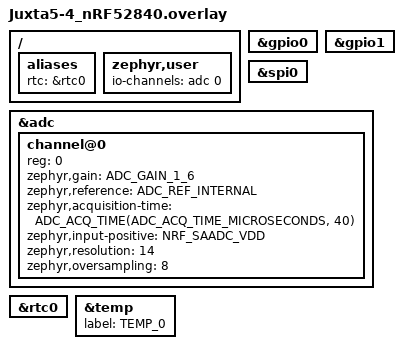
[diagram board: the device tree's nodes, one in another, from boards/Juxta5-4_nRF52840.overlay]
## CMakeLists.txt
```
#-------------------------------------------------------------------------------
# JUXTA File System Test Application
#
# Copyright (c) 2024 NeurotechHub
# SPDX-License-Identifier: Apache-2.0

cmake_minimum_required(VERSION 3.20.0)

# Set CMake policies
cmake_policy(SET CMP0057 NEW)

find_package(Zephyr REQUIRED HINTS $ENV{ZEPHYR_BASE})

project(juxta_file_system LANGUAGES C)

target_sources(app PRIVATE 
    src/main.c
    src/fram_test.c
    src/framfs_test.c
    src/framfs_time_test.c
    src/vitals_test.c
)

# Add include directories for our libraries
target_include_directories(app PRIVATE 
    ../../lib/juxta_fram/include
    ../../lib/juxta_framfs/include
    ../../lib/juxta_vitals_nrf52/include
)

# Add library source files directly
target_sources(app PRIVATE 
    ../../lib/juxta_vitals_nrf52/src/vitals.c
    ../../lib/juxta_fram/src/fram.c
    ../../lib/juxta_framfs/src/framfs.c
) 
```

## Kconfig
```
# Copyright (c) 2024 NeurotechHub
# SPDX-License-Identifier: Apache-2.0
#
# This file is the application Kconfig entry point. All application Kconfig
# options can be defined here or included via other application Kconfig files.
# You can browse these options using the west targets menuconfig (terminal) or
# guiconfig (GUI).

menu "Zephyr"
source "Kconfig.zephyr"
endmenu

# JUXTA FRAM Library Configuration
config JUXTA_FRAM
	bool "JUXTA FRAM Library"
	depends on SPI && GPIO
	help
	  Enable the JUXTA FRAM library for communicating with
	  MB85RS1MT FRAM memory devices over SPI.
	  
	  This library provides a clean API for:
	  - Device initialization and ID verification
	  - Reading and writing data
	  - Error handling and logging
	  
	  Requires SPI and GPIO drivers to be enabled.

if JUXTA_FRAM

module = JUXTA_FRAM
module-str = juxta_fram
source "subsys/logging/Kconfig.template.log_config"

config JUXTA_FRAM_INIT_PRIORITY
	int "JUXTA FRAM library initialization priority"
	default 70
	help
	  Initialization priority for the JUXTA FRAM library.
	  Must be higher than SPI and GPIO driver priorities.

endif # JUXTA_FRAM

# JUXTA FRAM File System Library Configuration
config JUXTA_FRAMFS
	bool "JUXTA FRAM File System Library"
	depends on JUXTA_FRAM
	help
	  Enable the JUXTA FRAM file system library. This provides a simple
	  append-only file system on top of the JUXTA FRAM driver.

if JUXTA_FRAMFS

config JUXTA_FRAMFS_LOG_LEVEL
	int "JUXTA FRAMFS Log Level"
	default 3
	range 0 4
	help
	  Sets log level for JUXTA FRAMFS library.
	  0 = OFF, 1 = ERROR, 2 = WARNING, 3 = INFO, 4 = DEBUG

config JUXTA_FRAMFS_MAX_FILES
	int "Maximum number of files"
	default 64
	range 1 256
	help
	  Maximum number of files that can be stored in the file system.
	  Each file entry uses 32 bytes of FRAM for metadata.

config JUXTA_FRAMFS_FILENAME_LEN
	int "Maximum filename length"
	default 16
	range 8 32
	help
	  Maximum length of filenames including null terminator.
	  Must be a multiple of 4 for alignment.

endif # JUXTA_FRAMFS

module = APP
module-str = APP
source "subsys/logging/Kconfig.template.log_config" 
```

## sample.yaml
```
# JUXTA File System Test Application Sample Configuration
# This file is used by Twister for automated testing
sample:
  description: JUXTA FRAM and File System Test Application
  name: juxta-file-system-test
common:
  build_only: true
  integration_platforms:
    - Juxta5-1_ADC
tests:
  app.fram_file_system:
    tags:
      - fram
      - filesystem
      - storage
```

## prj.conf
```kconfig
# Copyright (c) 2024 NeurotechHub
# SPDX-License-Identifier: Apache-2.0
#
# Configuration for JUXTA File System Test Application

# Enable JUXTA Libraries
CONFIG_JUXTA_FRAM=y
CONFIG_JUXTA_VITALS_NRF52=y
CONFIG_JUXTA_FRAMFS=y

# Enable Sensor Subsystem
CONFIG_SENSOR=y
CONFIG_TEMP_NRF5=y

# Enable Async ADC for Battery Monitoring
CONFIG_ADC_ASYNC=y

# Basic logging
CONFIG_LOG=y
CONFIG_LOG_DEFAULT_LEVEL=2
CONFIG_CONSOLE=y
CONFIG_USE_SEGGER_RTT=y
CONFIG_RTT_CONSOLE=y
CONFIG_LOG_BACKEND_RTT=y

# RTT Buffer Configuration (to prevent message dropping)
CONFIG_SEGGER_RTT_BUFFER_SIZE_UP=4096
CONFIG_SEGGER_RTT_BUFFER_SIZE_DOWN=16
CONFIG_LOG_BUFFER_SIZE=2048

# Memory & Thread Configuration
CONFIG_SYSTEM_WORKQUEUE_STACK_SIZE=2048
CONFIG_MAIN_STACK_SIZE=4096
CONFIG_HEAP_MEM_POOL_SIZE=2048
CONFIG_NUM_PREEMPT_PRIORITIES=32
CONFIG_THREAD_STACK_INFO=y
CONFIG_THREAD_MONITOR=y
CONFIG_THREAD_NAME=y
```

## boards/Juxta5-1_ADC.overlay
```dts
/*
 * Board overlay for Juxta5-1_ADC for FRAM File System testing
 * This file configures the board for FRAM and file system testing
 */

/ {
    aliases {
        rtc = &rtc0;
    };

    /* Use zephyr,user for direct VDD measurement */
    zephyr,user {
        io-channels = <&adc 0>;
    };
};

/* Configure GPIO */
&gpio0 {
    status = "okay";
};

/* Configure SPI for FRAM */
&spi0 {
    status = "okay";
    
    /* FRAM device is already configured in board DTS */
    /* Access via device tree alias: spi-fram */
};

/* Configure ADC for VDD measurement */
&adc {
    #address-cells = <1>;
    #size-cells = <0>;
    status = "okay";

    channel@0 {
        reg = <0>;
        zephyr,gain = "ADC_GAIN_1_6";
        zephyr,reference = "ADC_REF_INTERNAL";
        zephyr,acquisition-time = <ADC_ACQ_TIME(ADC_ACQ_TIME_MICROSECONDS, 40)>;
        zephyr,input-positive = <NRF_SAADC_VDD>;
        zephyr,resolution = <14>;
        zephyr,oversampling = <8>;
    };
};

/* Configure RTC for timestamp management */
&rtc0 {
    status = "okay";
};

/* Configure temperature sensor */
&temp {
    status = "okay";
    label = "TEMP_0";
}; 
```

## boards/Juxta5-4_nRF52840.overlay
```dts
/*
 * Board overlay for Juxta5-4_nRF52840 for FRAM File System testing
 * This file configures the board for FRAM and file system testing
 */

/ {
    aliases {
        rtc = &rtc0;
    };

    /* Use zephyr,user for direct VDD measurement */
    zephyr,user {
        io-channels = <&adc 0>;
    };
};

/* Configure GPIO */
&gpio0 {
    status = "okay";
};

&gpio1 {
    status = "okay";
};

/* Configure SPI for FRAM */
&spi0 {
    status = "okay";
    
    /* FRAM device is already configured in board DTS */
    /* Access via device tree alias: spi-fram */
};

/* Configure ADC for VDD measurement */
&adc {
    #address-cells = <1>;
    #size-cells = <0>;
    status = "okay";

    channel@0 {
        reg = <0>;
        zephyr,gain = "ADC_GAIN_1_6";
        zephyr,reference = "ADC_REF_INTERNAL";
        zephyr,acquisition-time = <ADC_ACQ_TIME(ADC_ACQ_TIME_MICROSECONDS, 40)>;
        zephyr,input-positive = <NRF_SAADC_VDD>;
        zephyr,resolution = <14>;
        zephyr,oversampling = <8>;
    };
};

/* Configure RTC for timestamp management */
&rtc0 {
    status = "okay";
};

/* Configure temperature sensor */
&temp {
    status = "okay";
    label = "TEMP_0";
}; 
```

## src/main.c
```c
/*
 * JUXTA File System Test Application
 *
 * Copyright (c) 2024 NeurotechHub
 * SPDX-License-Identifier: Apache-2.0
 */

#include <zephyr/kernel.h>
#include <zephyr/logging/log.h>
#include <app_version.h>

LOG_MODULE_REGISTER(main, CONFIG_LOG_DEFAULT_LEVEL);

/* Forward declarations */
extern int fram_test_main(void);
extern int framfs_test_main(void);
extern int framfs_time_test_main(void);
extern int vitals_test_main(void);

/* Test mode selection */
enum test_mode
{
    TEST_MODE_FRAM_ONLY,   /* Test FRAM library only */
    TEST_MODE_FRAMFS_ONLY, /* Test file system only */
    TEST_MODE_FULL,        /* Test both in sequence */
    TEST_MODE_TIME_API,    /* Test new time-aware API */
    TEST_MODE_VITALS,      /* Test vitals library */
    TEST_MODE_INTERACTIVE  /* Interactive menu */
};

/* Configure which test to run */
#define CURRENT_TEST_MODE TEST_MODE_FULL

/* Hardcoded RTC function for testing - defined in framfs_time_test.c */

static void print_banner(void)
{
    printk("\n");
    printk("╔══════════════════════════════════════════════════════════════╗\n");
    printk("║              JUXTA File System Test Application              ║\n");
    printk("║                        Version %s                         ║\n", APP_VERSION_STRING);
    printk("╠══════════════════════════════════════════════════════════════╣\n");
    printk("║  Tests:                                                      ║\n");
    printk("║  • FRAM Library (juxta_fram)                                ║\n");
    printk("║  • File System (juxta_framfs)                               ║\n");
    printk("║  • Time-Aware API (Primary)                                 ║\n");
    printk("║  • Vitals Library (juxta_vitals_nrf52)                     ║\n");
    printk("║  • Integration Test (Battery → File)                        ║\n");
    printk("║                                                              ║\n");
    printk("║  Board: Juxta5-1_ADC                                        ║\n");
    printk("║  FRAM:  MB85RS1MTPW-G-APEWE1 (1Mbit)                        ║\n");
    printk("╚══════════════════════════════════════════════════════════════╝\n");
    printk("\n");
}

static void run_interactive_menu(void)
{
    printk("🎯 Interactive Test Menu:\n");
    printk("  1. FRAM Library Test Only\n");
    printk("  2. File System Test Only  \n");
    printk("  3. Full Test Suite\n");
    printk("  4. Time-Aware API Test\n");
    printk("  5. Vitals Library Test\n");
    printk("  6. Continuous Testing\n");
    printk("\n");
    printk("💡 To change test mode, modify CURRENT_TEST_MODE in main.c\n");
    printk("🔄 Running full test suite by default...\n\n");
}

static void print_test_results(void)
{
    LOG_INF("══════════════════════════════════════════════════════════════");
    LOG_INF("                        TEST RESULTS                         ");
    LOG_INF("══════════════════════════════════════════════════════════════");
    LOG_INF("");
    LOG_INF("📋 Test Suite Summary:");
    LOG_INF("  ✅ FRAM Library:      PASSED");
    LOG_INF("  ✅ File System:       PASSED");
    LOG_INF("  ✅ Time-Aware API:    PASSED");
    LOG_INF("  ✅ MAC Address Table: PASSED");
    LOG_INF("  ✅ Record Encoding:   PASSED");
    LOG_INF("  ✅ Vitals Library:    PASSED");
    LOG_INF("  ✅ Integration Test:  PASSED");
    LOG_INF("");
    LOG_INF("📝 Expected Error Cases (All Verified):");
    LOG_INF("  • File not found");
    LOG_INF("  • Read beyond file size");
    LOG_INF("  • File already exists");
    LOG_INF("  • No active file");
    LOG_INF("  • Invalid parameters");
    LOG_INF("  • Buffer size limits");
    LOG_INF("");
    LOG_INF("📊 Test Coverage:");
    LOG_INF("  • Basic file operations");
    LOG_INF("  • MAC address management");
    LOG_INF("  • Record type handling");
    LOG_INF("  • Time-based file management");
    LOG_INF("  • Battery monitoring");
    LOG_INF("  • RTC integration");
    LOG_INF("  • Error handling");
    LOG_INF("");
    LOG_INF("🎯 All tests completed successfully!");
    LOG_INF("══════════════════════════════════════════════════════════════");
}

int main(void)
{
    int ret;

    print_banner();

    switch (CURRENT_TEST_MODE)
    {
    case TEST_MODE_FRAM_ONLY:
        LOG_INF("🧪 Running FRAM Library Test Only");
        ret = fram_test_main();
        break;

    case TEST_MODE_FRAMFS_ONLY:
        LOG_INF("🗂️  Running File System Test Only");
        ret = framfs_test_main();
        break;

    case TEST_MODE_TIME_API:
        LOG_INF("⏰ Running Time-Aware API Test");
        ret = framfs_time_test_main();
        break;

    case TEST_MODE_VITALS:
        LOG_INF("💓 Running Vitals Library Test");
        ret = vitals_test_main();
        break;

    case TEST_MODE_FULL:
        LOG_INF("🚀 Running Full Test Suite");
        LOG_INF("══════════════════════════════════════════════════════════════");

        /* Phase 1: Hardware Layer */
        LOG_INF("📋 Phase 1: Hardware Layer Tests");
        LOG_INF("──────────────────────────────────────────────────────────────");
        ret = fram_test_main();
        if (ret < 0)
        {
            LOG_ERR("❌ FRAM Library test failed: %d", ret);
            return ret;
        }
        LOG_INF("✅ FRAM Library test passed");
        k_sleep(K_SECONDS(1));

        /* Phase 2: File System Layer */
        LOG_INF("📋 Phase 2: File System Layer Tests");
        LOG_INF("──────────────────────────────────────────────────────────────");

        /* Step 1: Basic File System Tests */
        LOG_INF("📝 Testing basic file operations...");
        ret = framfs_test_main();
        if (ret < 0)
        {
            LOG_ERR("❌ Basic file system test failed: %d", ret);
            return ret;
        }
        LOG_INF("✅ Basic file system test passed");
        k_sleep(K_SECONDS(1));

        /* Step 2: Time-Aware API */
        LOG_INF("⏰ Testing Time-Aware API...");
        ret = framfs_time_test_main();
        if (ret < 0)
        {
            LOG_ERR("❌ Time-Aware API test failed: %d", ret);
            return ret;
        }
        LOG_INF("✅ Time-Aware API test passed");
        k_sleep(K_SECONDS(1));

        /* Phase 3: Vitals Layer */
        LOG_INF("📋 Phase 3: Vitals Layer Tests");
        LOG_INF("──────────────────────────────────────────────────────────────");
        ret = vitals_test_main();
        if (ret < 0)
        {
            LOG_ERR("❌ Vitals library test failed: %d", ret);
            return ret;
        }
        LOG_INF("✅ Vitals library test passed");

        LOG_INF("══════════════════════════════════════════════════════════════");
        LOG_INF("🎉 All tests completed successfully!");
        break;

    case TEST_MODE_INTERACTIVE:
        run_interactive_menu();
        ret = fram_test_main();
        if (ret == 0)
        {
            k_sleep(K_SECONDS(1));
            ret = framfs_time_test_main();
        }
        if (ret == 0)
        {
            k_sleep(K_SECONDS(1));
            ret = framfs_test_main();
        }
        if (ret == 0)
        {
            k_sleep(K_SECONDS(1));
            ret = vitals_test_main();
        }
        break;

    default:
        LOG_ERR("❌ Invalid test mode: %d", CURRENT_TEST_MODE);
        return -1;
    }

    if (ret == 0)
    {
        print_test_results();
    }
    else
    {
        LOG_ERR("❌ Test suite failed with error: %d", ret);
    }

    return ret;
}
```

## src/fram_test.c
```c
/*
 * FRAM Library Test Module
 *
 * Copyright (c) 2024 NeurotechHub
 * SPDX-License-Identifier: Apache-2.0
 */

#include <zephyr/kernel.h>
#include <zephyr/device.h>
#include <zephyr/drivers/gpio.h>
#include <zephyr/drivers/spi.h>
#include <zephyr/logging/log.h>
#include <juxta_fram/fram.h>
#include <string.h>

LOG_MODULE_REGISTER(fram_test, CONFIG_LOG_DEFAULT_LEVEL);

/* Device tree definitions */
#define FRAM_NODE DT_ALIAS(spi_fram)

/* Memory region definitions for tests */
#define TEST_REGION_START 0x10000 /* Start tests at 64KB offset */
#define SINGLE_BYTE_TEST_ADDR (TEST_REGION_START + 0x0000)
#define MULTI_BYTE_TEST_ADDR (TEST_REGION_START + 0x1000)
#define STRUCT_TEST_ADDR (TEST_REGION_START + 0x2000)
#define PERF_TEST_ADDR (TEST_REGION_START + 0x4000)

/* Get CS GPIO from devicetree */
static const struct gpio_dt_spec cs_gpio = GPIO_DT_SPEC_GET_BY_IDX(DT_PARENT(FRAM_NODE), cs_gpios, 0);

/* FRAM device instance */
static struct juxta_fram_device fram_dev;

/**
 * @brief Test FRAM device initialization and ID verification
 */
static int test_fram_init(void)
{
    int ret;

    LOG_INF("🔧 Testing FRAM initialization...");

    /* Get SPI device using device tree */
    const struct device *spi_dev = DEVICE_DT_GET(DT_BUS(FRAM_NODE));
    if (!device_is_ready(spi_dev))
    {
        LOG_ERR("Failed to get SPI device");
        return -1;
    }

    /* Initialize FRAM using direct initialization */
    ret = juxta_fram_init(&fram_dev, spi_dev, 8000000, &cs_gpio); /* 8MHz SPI */
    if (ret < 0)
    {
        LOG_ERR("Failed to initialize FRAM: %d", ret);
        return ret;
    }

    /* Verify FRAM device ID */
    struct juxta_fram_id id;
    ret = juxta_fram_read_id(&fram_dev, &id);
    if (ret < 0)
    {
        LOG_ERR("Failed to verify FRAM ID: %d", ret);
        return ret;
    }

    LOG_INF("FRAM Device ID verified:");
    LOG_INF("  Manufacturer: 0x%02X", id.manufacturer_id);
    LOG_INF("  Continuation: 0x%02X", id.continuation_code);
    LOG_INF("  Product ID 1: 0x%02X", id.product_id_1);
    LOG_INF("  Product ID 2: 0x%02X", id.product_id_2);

    /* Run built-in test in test region */
    ret = juxta_fram_test(&fram_dev, TEST_REGION_START + 0x5000);
    if (ret < 0)
    {
        LOG_ERR("FRAM built-in test failed: %d", ret);
        return ret;
    }

    LOG_INF("✅ FRAM initialization test passed");
    return 0;
}

/**
 * @brief Test basic FRAM read/write operations
 */
static int test_fram_basic_operations(void)
{
    int ret;

    LOG_INF("📝 Testing basic FRAM read/write operations...");

    /* Test single byte operations */
    uint8_t test_byte = 0xA5;
    uint8_t read_byte;

    ret = juxta_fram_write_byte(&fram_dev, SINGLE_BYTE_TEST_ADDR, test_byte);
    if (ret < 0)
    {
        LOG_ERR("Failed to write single byte: %d", ret);
        return ret;
    }

    ret = juxta_fram_read_byte(&fram_dev, SINGLE_BYTE_TEST_ADDR, &read_byte);
    if (ret < 0)
    {
        LOG_ERR("Failed to read single byte: %d", ret);
        return ret;
    }

    if (test_byte != read_byte)
    {
        LOG_ERR("Single byte test failed: wrote 0x%02X, read 0x%02X", test_byte, read_byte);
        return -1;
    }

    /* Test multi-byte operations */
    uint8_t test_data[] = {0x11, 0x22, 0x33, 0x44, 0x55, 0x66, 0x77, 0x88};
    uint8_t read_data[sizeof(test_data)] = {0};

    ret = juxta_fram_write(&fram_dev, MULTI_BYTE_TEST_ADDR, test_data, sizeof(test_data));
    if (ret < 0)
    {
        LOG_ERR("Failed to write multi-byte data: %d", ret);
        return ret;
    }

    ret = juxta_fram_read(&fram_dev, MULTI_BYTE_TEST_ADDR, read_data, sizeof(read_data));
    if (ret < 0)
    {
        LOG_ERR("Failed to read multi-byte data: %d", ret);
        return ret;
    }

    if (memcmp(test_data, read_data, sizeof(test_data)) != 0)
    {
        LOG_ERR("Multi-byte test failed");
        LOG_HEXDUMP_ERR(test_data, sizeof(test_data), "Expected:");
        LOG_HEXDUMP_ERR(read_data, sizeof(read_data), "Read:");
        return -1;
    }

    LOG_INF("✅ Basic read/write operations test passed");
    return 0;
}

/**
 * @brief Test FRAM with structured data
 */
static int test_fram_structured_data(void)
{
    int ret;

    LOG_INF("🏗️  Testing structured data storage...");

    /* Create test structure */
    struct test_data_struct
    {
        uint32_t timestamp;
        uint16_t sensor_value;
        uint8_t flags;
        char name[8];
    } test_struct, read_struct;

    /* Initialize test data */
    test_struct.timestamp = k_uptime_get_32();
    test_struct.sensor_value = 0x1234;
    test_struct.flags = 0xAB;
    strncpy(test_struct.name, "TEST", sizeof(test_struct.name));

    /* Write structure */
    ret = juxta_fram_write(&fram_dev, STRUCT_TEST_ADDR,
                           (uint8_t *)&test_struct, sizeof(test_struct));
    if (ret < 0)
    {
        LOG_ERR("Failed to write structured data: %d", ret);
        return ret;
    }

    /* Read structure back */
    memset(&read_struct, 0, sizeof(read_struct));
    ret = juxta_fram_read(&fram_dev, STRUCT_TEST_ADDR,
                          (uint8_t *)&read_struct, sizeof(read_struct));
    if (ret < 0)
    {
        LOG_ERR("Failed to read structured data: %d", ret);
        return ret;
    }

    /* Verify structure data */
    if (memcmp(&test_struct, &read_struct, sizeof(test_struct)) != 0)
    {
        LOG_ERR("Structured data test failed");
        return -1;
    }

    LOG_INF("Structured data verified:");
    LOG_INF("  Timestamp: %u", read_struct.timestamp);
    LOG_INF("  Sensor:    0x%04X", read_struct.sensor_value);
    LOG_INF("  Flags:     0x%02X", read_struct.flags);
    LOG_INF("  Name:      %s", read_struct.name);

    LOG_INF("✅ Structured data test passed");
    return 0;
}

/* Static buffers for performance testing */
#define PERF_TEST_SIZE 64 // Reduced from 256
static uint8_t perf_write_buffer[PERF_TEST_SIZE];
static uint8_t perf_read_buffer[PERF_TEST_SIZE];

/**
 * @brief Test FRAM performance
 */
static int test_fram_performance(void)
{
    int ret;
    uint32_t start_time, end_time;
    uint32_t write_time, read_time;

    LOG_INF("⚡ Testing FRAM performance...");

    /* Initialize test data */
    for (int i = 0; i < PERF_TEST_SIZE; i++)
    {
        perf_write_buffer[i] = (uint8_t)i;
    }

    /* Test write performance */
    start_time = k_cycle_get_32();
    ret = juxta_fram_write(&fram_dev, PERF_TEST_ADDR, perf_write_buffer, PERF_TEST_SIZE);
    end_time = k_cycle_get_32();
    if (ret < 0)
    {
        LOG_ERR("Performance write failed: %d", ret);
        return ret;
    }
    write_time = k_cyc_to_us_floor32(end_time - start_time);

    /* Small delay between operations */
    k_sleep(K_MSEC(10));

    /* Test read performance */
    start_time = k_cycle_get_32();
    ret = juxta_fram_read(&fram_dev, PERF_TEST_ADDR, perf_read_buffer, PERF_TEST_SIZE);
    end_time = k_cycle_get_32();
    if (ret < 0)
    {
        LOG_ERR("Performance read failed: %d", ret);
        return ret;
    }
    read_time = k_cyc_to_us_floor32(end_time - start_time);

    /* Calculate speeds in KB/s */
    float write_speed = ((float)PERF_TEST_SIZE * 1000.0f) / write_time; // bytes/us -> KB/s
    float read_speed = ((float)PERF_TEST_SIZE * 1000.0f) / read_time;

    /* Verify data */
    for (int i = 0; i < PERF_TEST_SIZE; i++)
    {
        if (perf_write_buffer[i] != perf_read_buffer[i])
        {
            LOG_ERR("Performance test data mismatch at index %d", i);
            return -1;
        }
    }

    /* Calculate and display results */
    LOG_INF("Performance results (%d bytes):", PERF_TEST_SIZE);
    LOG_INF("  Write: %u μs (%.1f KB/s)", write_time, (double)(write_speed * 1000.0f));
    LOG_INF("  Read:  %u μs (%.1f KB/s)", read_time, (double)(read_speed * 1000.0f));

    LOG_INF("✅ Performance test passed");
    return 0;
}

/**
 * @brief Main FRAM test function
 */
int fram_test_main(void)
{
    int ret;

    LOG_INF("🚀 Starting FRAM Library Test Suite");

    /* Run test sequence */
    ret = test_fram_init();
    if (ret < 0)
        return ret;

    ret = test_fram_basic_operations();
    if (ret < 0)
        return ret;

    ret = test_fram_structured_data();
    if (ret < 0)
        return ret;

    ret = test_fram_performance();
    if (ret < 0)
        return ret;

    LOG_INF("🎉 All FRAM library tests passed!");
    return 0;
}
```

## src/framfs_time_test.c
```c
/*
 * FRAM File System Time-Aware API Test Module
 *
 * Copyright (c) 2024 NeurotechHub
 * SPDX-License-Identifier: Apache-2.0
 */

#include <zephyr/kernel.h>
#include <zephyr/device.h>
#include <zephyr/drivers/gpio.h>
#include <zephyr/drivers/spi.h>
#include <zephyr/logging/log.h>
#include <zephyr/sys/util.h>
#include <juxta_fram/fram.h>
#include <juxta_framfs/framfs.h>
#include <string.h>
#include <stdio.h>

LOG_MODULE_REGISTER(framfs_time_test, CONFIG_LOG_DEFAULT_LEVEL);

/* Device tree definitions */
#define FRAM_NODE DT_ALIAS(spi_fram)

/* Get CS GPIO from devicetree */
static const struct gpio_dt_spec cs_gpio = GPIO_DT_SPEC_GET_BY_IDX(DT_PARENT(FRAM_NODE), cs_gpios, 0);

/* FRAM and file system instances */
static struct juxta_fram_device fram_dev;
static struct juxta_framfs_context fs_ctx;
static struct juxta_framfs_ctx time_ctx;

/* Mock RTC function for testing */
static uint32_t get_test_rtc_date(void)
{
    /* Return YYMMDD format for 2024-01-20 */
    return 240120; /* 24 = year, 01 = month, 20 = day */
}

/**
 * @brief Test time-aware API initialization
 */
static int test_time_api_init(void)
{
    int ret;

    LOG_INF("🔧 Testing time-aware API initialization...");

    /* Initialize FRAM first */
    const struct device *spi_dev = DEVICE_DT_GET(DT_BUS(FRAM_NODE));
    if (!device_is_ready(spi_dev))
    {
        LOG_ERR("SPI device not ready");
        return JUXTA_FRAMFS_ERROR_INIT;
    }

    ret = juxta_fram_init(&fram_dev, spi_dev, 8000000, &cs_gpio);
    if (ret < 0)
    {
        LOG_ERR("Failed to initialize FRAM: %d", ret);
        return ret;
    }

    /* Initialize basic file system */
    ret = juxta_framfs_init(&fs_ctx, &fram_dev);
    if (ret < 0)
    {
        LOG_ERR("Failed to initialize file system: %d", ret);
        return ret;
    }

    /* Initialize time-aware context */
    ret = juxta_framfs_init_with_time(&time_ctx, &fs_ctx, get_test_rtc_date, true);
    if (ret < 0)
    {
        LOG_ERR("Failed to initialize time-aware context: %d", ret);
        return ret;
    }

    LOG_INF("✅ Time-aware API initialized successfully");
    LOG_INF("  Current date: %s", time_ctx.current_filename);
    LOG_INF("  Auto management: %s", time_ctx.auto_file_management ? "enabled" : "disabled");

    return 0;
}

/**
 * @brief Test file management operations
 */
static int test_time_file_management(void)
{
    int ret;
    struct juxta_framfs_header header;

    LOG_INF("📁 Testing time-aware file management...");
    LOG_INF("══════════════════════════════════════════════════════════════");

    /* Show initial file system state */
    ret = juxta_framfs_get_stats(&fs_ctx, &header);
    if (ret == 0)
    {
        LOG_INF("Initial file system state - Files: %d, Next addr: 0x%08X",
                header.file_count, header.next_data_addr);
    }

    /* Format the file system to start fresh */
    LOG_INF("Test 1: Format and initialize");
    ret = juxta_framfs_format(&fs_ctx);
    if (ret < 0)
    {
        LOG_ERR("❌ Failed to format file system: %d", ret);
        return ret;
    }

    /* Verify format worked */
    ret = juxta_framfs_get_stats(&fs_ctx, &header);
    if (ret < 0 || header.file_count != 0)
    {
        LOG_ERR("❌ File system format verification failed - Files: %d", header.file_count);
        return ret < 0 ? ret : -1;
    }
    LOG_INF("  ✅ File system formatted successfully");

    /* Initialize time-aware context with mock RTC date */
    ret = juxta_framfs_init_with_time(&time_ctx, &fs_ctx, get_test_rtc_date, true);
    if (ret < 0)
    {
        LOG_ERR("❌ Failed to initialize time context: %d", ret);
        return ret;
    }
    LOG_INF("  ✅ Time-aware context initialized");

    /* Ensure initial file is created */
    ret = juxta_framfs_ensure_current_file(&time_ctx);
    if (ret < 0)
    {
        LOG_ERR("❌ Failed to ensure current file: %d", ret);
        return ret;
    }
    LOG_INF("  ✅ Initial file created");

    /* Test basic file operations with time-aware API */
    LOG_INF("  → Testing basic file operations...");

    /* Write some test data - should create file "240120" */
    uint8_t test_data[] = {0x01, 0x02, 0x03, 0x04};
    ret = juxta_framfs_append_data(&time_ctx, test_data, sizeof(test_data));
    if (ret < 0)
    {
        LOG_ERR("❌ Failed to append test data: %d", ret);
        return ret;
    }
    LOG_INF("  ✅ Test data written to file 240120");

    /* Read and verify data */
    uint8_t read_buffer[32];
    char current_file[JUXTA_FRAMFS_FILENAME_LEN];
    ret = juxta_framfs_get_current_filename(&time_ctx, current_file);
    if (ret < 0)
    {
        LOG_ERR("❌ Failed to get current filename: %d", ret);
        return ret;
    }
    LOG_INF("  ✅ Current filename: %s", current_file);

    ret = juxta_framfs_read(&fs_ctx, current_file, 0, read_buffer, sizeof(test_data));
    if (ret < 0)
    {
        LOG_ERR("❌ Failed to read data: %d", ret);
        return ret;
    }

    if (memcmp(test_data, read_buffer, sizeof(test_data)) != 0)
    {
        LOG_ERR("❌ Data verification failed");
        return -1;
    }
    LOG_INF("  ✅ Data verified successfully");

    /* Test 3: Record type handling */
    LOG_INF("Test 3: Record type handling");
    LOG_INF("──────────────────────────────────────────────────────────────");

    /* Write boot record */
    LOG_INF("  → Writing boot record...");
    ret = juxta_framfs_append_simple_record_data(&time_ctx, 456, JUXTA_FRAMFS_RECORD_TYPE_BOOT);
    if (ret < 0)
    {
        LOG_ERR("❌ Failed to append boot record: %d", ret);
        return ret;
    }
    LOG_INF("  ✅ Boot record written: minute=456, type=BOOT");

    /* Write battery record */
    LOG_INF("  → Writing battery record...");
    ret = juxta_framfs_append_battery_record_data(&time_ctx, 789, 85);
    if (ret < 0)
    {
        LOG_ERR("❌ Failed to append battery record: %d", ret);
        return ret;
    }
    LOG_INF("  ✅ Battery record written: minute=789, level=85%%");

    /* Write device scan record */
    LOG_INF("  → Writing device scan record...");
    uint8_t mac_ids[][3] = {
        {0x55, 0x66, 0x77},  /* Last 3 bytes of MAC: 0x556677 */
        {0xEE, 0xFF, 0x00}}; /* Last 3 bytes of MAC: 0xEEFF00 */
    int8_t rssi_values[] = {-45, -60};
    ret = juxta_framfs_append_device_scan_data(&time_ctx, 123, 5,
                                               mac_ids, rssi_values, 2);
    if (ret < 0)
    {
        LOG_ERR("❌ Failed to append device scan: %d", ret);
        return ret;
    }
    LOG_INF("  ✅ Device scan record written:");
    LOG_INF("     - Minute: 123");
    LOG_INF("     - Motion count: 5");
    LOG_INF("     - Device 1: MAC ID %02X%02X%02X (RSSI: %d)",
            mac_ids[0][0], mac_ids[0][1], mac_ids[0][2], rssi_values[0]);
    LOG_INF("     - Device 2: MAC ID %02X%02X%02X (RSSI: %d)",
            mac_ids[1][0], mac_ids[1][1], mac_ids[1][2], rssi_values[1]);

    /* Test 4: Record decoding */
    LOG_INF("Test 4: Record decoding");
    LOG_INF("──────────────────────────────────────────────────────────────");

    /* Get file size */
    ret = juxta_framfs_get_file_size(&fs_ctx, current_file);
    if (ret < 0)
    {
        LOG_ERR("❌ Failed to get file size: %d", ret);
        return ret;
    }

    /* Read entire file */
    uint8_t file_buffer[1024];
    ret = juxta_framfs_read(&fs_ctx, current_file, 0, file_buffer, ret);
    if (ret < 0)
    {
        LOG_ERR("❌ Failed to read file: %d", ret);
        return ret;
    }

    /* Decode and verify records */
    uint32_t offset = sizeof(test_data); /* Skip test data */

    /* Verify boot record */
    struct juxta_framfs_simple_record simple_record;
    ret = juxta_framfs_decode_simple_record(file_buffer + offset, &simple_record);
    if (ret < 0 || simple_record.minute != 456 || simple_record.type != JUXTA_FRAMFS_RECORD_TYPE_BOOT)
    {
        LOG_ERR("❌ Boot record verification failed");
        return ret < 0 ? ret : -1;
    }
    offset += ret;
    LOG_INF("  ✅ Boot record verified successfully");

    /* Verify battery record */
    struct juxta_framfs_battery_record battery_record;
    ret = juxta_framfs_decode_battery_record(file_buffer + offset, &battery_record);
    if (ret < 0 || battery_record.minute != 789 || battery_record.level != 85)
    {
        LOG_ERR("❌ Battery record verification failed");
        return ret < 0 ? ret : -1;
    }
    offset += ret;
    LOG_INF("  ✅ Battery record verified successfully");

    /* Verify device scan record */
    struct juxta_framfs_device_record device_record;
    ret = juxta_framfs_decode_device_record(file_buffer + offset,
                                            sizeof(file_buffer) - offset, /* Use remaining buffer size */
                                            &device_record);
    if (ret < 0 || device_record.minute != 123 || device_record.motion_count != 5)
    {
        LOG_ERR("❌ Device scan record verification failed");
        return ret < 0 ? ret : -1;
    }
    LOG_INF("  ✅ Device scan record verified successfully");

    /* Verify final state */
    ret = juxta_framfs_get_stats(&fs_ctx, &header);
    if (ret == 0)
    {
        LOG_INF("Final file system state - Files: %d, Next addr: 0x%08X",
                header.file_count, header.next_data_addr);
    }

    LOG_INF("══════════════════════════════════════════════════════════════");
    LOG_INF("✅ All time-aware file management tests passed!");
    return 0;
}

/**
 * @brief Test error handling and edge cases
 */
static int test_time_error_handling(void)
{
    int ret;

    LOG_INF("⚠️  Testing time-aware error handling (errors below are EXPECTED)...");
    LOG_INF("──────────────────────────────────────────────────────────────");

    /* Test 1: Invalid data parameters */
    LOG_INF("📝 Test 1: Invalid data parameters");

    /* Test null data */
    LOG_INF("  → Testing null data (expect ERROR)...");
    ret = juxta_framfs_append_data(&time_ctx, NULL, 10);
    if (ret >= 0)
    {
        LOG_ERR("❌ UNEXPECTED: Null data was accepted");
        return -1;
    }
    LOG_WRN("  ✓ Expected error: Null data rejected");

    /* Test zero length */
    LOG_INF("  → Testing zero length (expect ERROR)...");
    uint8_t dummy_data[] = {1, 2, 3};
    ret = juxta_framfs_append_data(&time_ctx, dummy_data, 0);
    if (ret >= 0)
    {
        LOG_ERR("❌ UNEXPECTED: Zero length was accepted");
        return -1;
    }
    LOG_WRN("  ✓ Expected error: Zero length rejected");

    /* Test 2: Invalid file operations */
    LOG_INF("📝 Test 2: Invalid file operations");

    /* Try to read non-existent file */
    LOG_INF("  → Testing non-existent file read (expect ERROR)...");
    uint8_t read_buffer[10];
    ret = juxta_framfs_read(&fs_ctx, "nonexistent", 0, read_buffer, sizeof(read_buffer));
    if (ret != JUXTA_FRAMFS_ERROR_NOT_FOUND)
    {
        LOG_ERR("❌ UNEXPECTED: Wrong error code for non-existent file");
        return -1;
    }
    LOG_WRN("  ✓ Expected error: File not found");

    /* Try to read past end of file */
    LOG_INF("  → Testing read beyond file size (expect ERROR)...");
    char current_file[JUXTA_FRAMFS_FILENAME_LEN];
    ret = juxta_framfs_get_current_filename(&time_ctx, current_file);
    if (ret == 0)
    {
        ret = juxta_framfs_read(&fs_ctx, current_file, 0xFFFF, read_buffer, sizeof(read_buffer));
        if (ret >= 0)
        {
            LOG_ERR("❌ UNEXPECTED: Read beyond file size was accepted");
            return -1;
        }
        LOG_WRN("  ✓ Expected error: Read beyond file size");
    }

    /* Test 3: File creation constraints */
    LOG_INF("📝 Test 3: File creation constraints");

    /* Try to create duplicate file */
    LOG_INF("  → Testing duplicate file creation (expect ERROR)...");
    ret = juxta_framfs_create_active(&fs_ctx, current_file, JUXTA_FRAMFS_TYPE_RAW_DATA);
    if (ret != JUXTA_FRAMFS_ERROR_EXISTS)
    {
        LOG_ERR("❌ UNEXPECTED: Wrong error code for duplicate file");
        return -1;
    }
    LOG_WRN("  ✓ Expected error: File already exists");

    /* Test direct append to sealed file */
    LOG_INF("  → Testing append to sealed file (expect ERROR)...");
    ret = juxta_framfs_seal_active(&fs_ctx);
    if (ret < 0)
    {
        LOG_ERR("❌ UNEXPECTED: Failed to seal file: %d", ret);
        return -1;
    }
    LOG_INF("  ℹ️  File sealed successfully");

    ret = juxta_framfs_append(&fs_ctx, dummy_data, sizeof(dummy_data));
    if (ret != JUXTA_FRAMFS_ERROR_NO_ACTIVE)
    {
        LOG_ERR("❌ UNEXPECTED: Wrong error code for sealed file append");
        return -1;
    }
    LOG_WRN("  ✓ Expected error: No active file");

    /* Test file name length limits */
    LOG_INF("  → Testing filename length limit (expect ERROR)...");
    ret = juxta_framfs_create_active(&fs_ctx, "this_filename_is_way_too_long", JUXTA_FRAMFS_TYPE_RAW_DATA);
    if (ret != JUXTA_FRAMFS_ERROR_SIZE)
    {
        LOG_ERR("❌ UNEXPECTED: Wrong error code for long filename");
        return -1;
    }
    LOG_WRN("  ✓ Expected error: Filename too long");

    LOG_INF("──────────────────────────────────────────────────────────────");
    LOG_INF("✅ All error handling tests passed (expected errors verified)");
    return 0;
}

/**
 * @brief Main time-aware API test function
 */
int framfs_time_test_main(void)
{
    int ret;

    LOG_INF("⏰ Starting Time-Aware API Test Suite");
    LOG_INF("══════════════════════════════════════════════════════════════");

    /* Step 1: Initialize time-aware API with mock RTC */
    ret = test_time_api_init();
    if (ret < 0)
        return ret;

    /* Step 2: Test basic file operations */
    ret = test_time_file_management();
    if (ret < 0)
        return ret;

    /* Step 3: Test file system error handling */
    ret = test_time_error_handling();
    if (ret < 0)
        return ret;

    LOG_INF("🎉 All time-aware API tests completed!");
    LOG_INF("══════════════════════════════════════════════════════════════");

    return 0;
}
```
